# nrf54lm20a_enga_application register map
Vendor: Nordic Semiconductor; Series: nrf54l; File version: 1
CPU: CM33 r0p4, little endian, MPU, FPU, 3 interrupt priority bits, 270 interrupts, 4 SAU regions
Registers are 32-bit, read-write, reset 0x0 unless marked. A register's access mark holds for its fields unless they carry their own. Offsets are from the block's base; [hi:lo] are bit positions; lines under a group give offsets from that group; {n}, {i} and the like mark numbered series; 'fields as' and 'values as' point back to an identical list.

## GLOBAL_RADIO_NS (part 3 of 4) — 2.4 GHz radio 0
Base 0x4008A000
Same registers: GLOBAL_RADIO_S 0x5008A000
0x7D0 RXAGC group — Unspecified
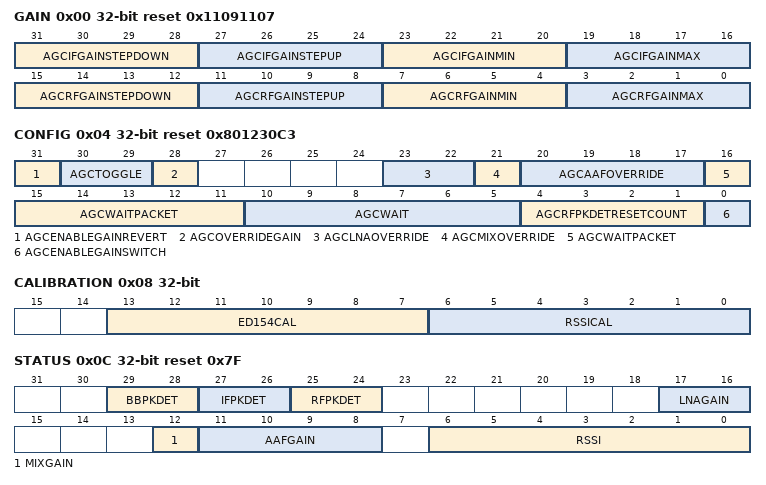
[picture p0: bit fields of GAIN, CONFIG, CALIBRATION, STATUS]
  0x00 GAIN reset 0x11091107 — Gain boundary settings and gain steps
    [31:28] AGCIFGAINSTEPDOWN — gain step for decreasing IF gain
    [27:24] AGCIFGAINSTEPUP — gain step for increasing IF gain
    [23:20] AGCIFGAINMIN — Minimum gain of IF gain
    [19:16] AGCIFGAINMAX — Maximum gain of IF gain
    [15:12] AGCRFGAINSTEPDOWN — gain step for decreasing RF gain
    [11:8] AGCRFGAINSTEPUP — gain step for increasing RF gain
    [7:4] AGCRFGAINMIN — Minimum gain of RF gain
    [3:0] AGCRFGAINMAX — Maximum gain of RF gain
  0x04 CONFIG reset 0x801230C3 — Configuration to adjust gain control loop
    [31] AGCENABLEGAINREVERT — Gain reversion. 0: reduce IF gain before RF gain, 1: reduce RF gain before IF gain.
    [30:29] AGCTOGGLE — Enable(1) or disable(0) functional testmode for AGC
    [28] AGCOVERRIDEGAIN — 0: AGC takes control of all gains, 1: Control all gains (aafGain, mixGain, lnaGain) from registers
    [23:22] AGCLNAOVERRIDE — Override value for lnaGain
    [21] AGCMIXOVERRIDE — Override value for mixGain
    [20:17] AGCAAFOVERRIDE — Override value for aafGain
    [16:11] AGCWAITPACKET — The number of clock cycles between each adjustment of the gain while addressMatch is high
    [10:5] AGCWAIT — The number of clock cycles between each adjustment of the gain while addressMatch is low
    [4:1] AGCRFPKDETRESETCOUNT — The number of clock cycles after the adjustment of gain that the reset signal to the RF peak detector is set high
    [0] AGCENABLEGAINSWITCH — Causes the RF gain to be decreased and the IF gain to be increased if the overall gain can be maintained
  0x08 CALIBRATION — Calibrate RSSI and Energy Detect values
    [13:7] ED154CAL — 802154 Energy Detect calibration value
    [6:0] RSSICAL — RSSI calibration value (this field affects the value of both RSSISAMPLE and EDSAMPLE)
  0x0C STATUS ro reset 0x7F — Readout latest gain control status
    [29:28] BBPKDET — BB peak detector output. Represent state[1:0] in RxAgc.
    [27:26] IFPKDET — IF peak detector output. Represent state[3:2] in RxAgc.
    [25:24] RFPKDET — RF peak detector output after sync. Represent state[5:4] in RxAgc.
    [17:16] LNAGAIN — Raw LNA gain status
    [12] MIXGAIN — Raw mixer gain status
    [11:8] AAFGAIN — Raw AAF gain status
    [6:0] RSSI — Raw status of received signal strength indicator, directly from RxAgc without buffering
0x7E4 RXIF group — Unspecified
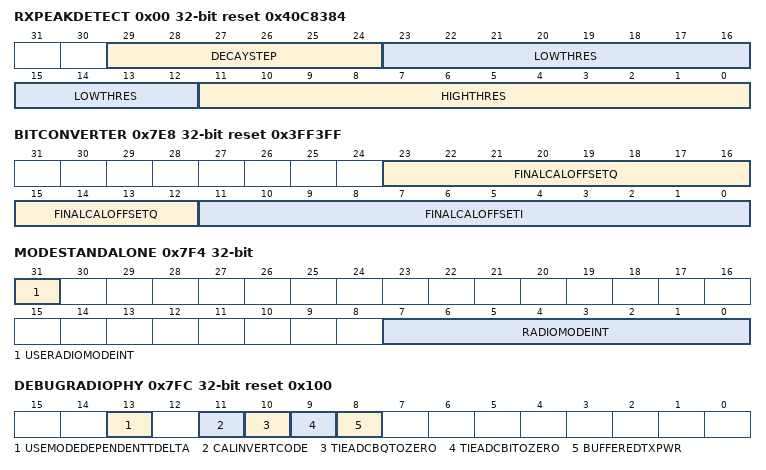
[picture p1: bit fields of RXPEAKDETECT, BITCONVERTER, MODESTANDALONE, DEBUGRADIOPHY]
  0x00 RXPEAKDETECT reset 0x40C8384 — Configuration of IF Rx peak detector
    [29:24] DECAYSTEP — Constant output reduction step
    [23:12] LOWTHRES — Low threshold of IF peak detector. This valued is based on the 11-bits ADC of SPHYNX_ANA.
    [11:0] HIGHTHRES — High threshold of IF peak detector. This valued is based on the 11-bits ADC of SPHYNX_ANA.
0x7E8 BITCONVERTER reset 0x3FF3FF — Configuration of ADC output to digital front-end
  [23:12] FINALCALOFFSETQ — ADC offset compensation of channel Q (unsigned)
  [11:0] FINALCALOFFSETI — ADC offset compensation of channel I (unsigned)
0x7F4 MODESTANDALONE — Data rate and modulation when SPHYNX in standalone mode
  [31] USERADIOMODEINT — 0: use radioMode/radioModeUpdate from port (controlled from top), 1: use radioMode/radioModeUpdate from registers in this IP
  [7:0] RADIOMODEINT — Internal radio mode consists of sSel, zeroIf, deModN and mode[3:0]
0x7FC DEBUGRADIOPHY reset 0x100 — Debug for radio PHY
  [13] USEMODEDEPENDENTTDELTA — 1: use TDELTAPIPE and TDELTAPWRDNPA from MODEDEPENDENT register instead of TIMINGTX2
  [11] CALINVERTCODE — 1: Invert all calibration codes
  [10] TIEADCBQTOZERO — 0: output normal adcBinaryBQ, 1: tie adcBinaryBQ to zero
  [9] TIEADCBITOZERO — 0: output normal adcBinaryBI, 1: tie adcBinaryBI to zero
  [8] BUFFEREDTXPWR — Set to high to buffer TXPOWER so that sub-modules in the MMI will only update next tx power config at TX_EN, RX_EN and LB_EN. Set to low if special test is needed for Tx test.
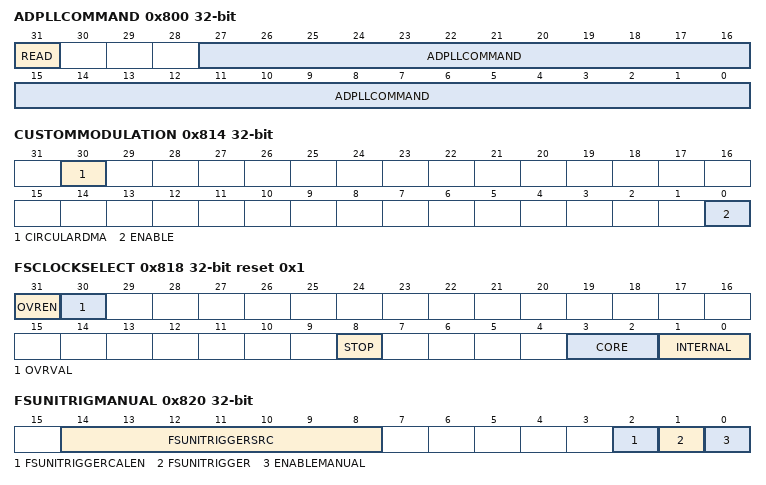
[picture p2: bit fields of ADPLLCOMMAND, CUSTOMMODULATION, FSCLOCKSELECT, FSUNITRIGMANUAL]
0x800 ADPLLCOMMAND — Send or receive command directly to the AdPll digital island. Only write to this register when FSASYNCBUSBUSY returns 0
  [31] READ — When 1, a read transaction is initiated. When the event COMPLETETRANS is set, read back this register
  [27:0] ADPLLCOMMAND — Controls the asynch interface, bits[27:16] are address, bits [15:0] are command/data field
0x804 FSFREQFINETUNE — Allows fine-tuning the RF frequency with a very fine resolution
  [12:0] FSFREQFINETUNE — 2-complement number for fine-tuning the frequency in steps of 488.28 Hz
0x808 DEVIATION reset 0x55 — Frequency deviation for modulation
  [9:0] DEVIATION
0x80C MODRATE reset 0x2 — Select modulation rate
  [2:0] MODRATE
    0=250Kbit (250 kbps); 1=500Kbit (500 kbps); 2=1Mbit (1 Mbps); 3=2Mbit (2 Mbps); 4=4Mbit (4 Mbps)
0x810 MODFILTERING reset 0x2 — Select gaussian filtering mode
  [2:0] MODFILTERING
    0=None (No filtering); 1=1bt00 (Gfsk Bt=1.00); 2=0bt60 (Gfsk Bt=0.60); 3=2bt00 (Gfsk Bt=2.00); 4=0bt40 (Gfsk Bt=0.40); 5=0bt45 (Gfsk Bt=0.45); 6=0bt50 (Gfsk Bt=0.50); 7=0bt55 (Gfsk Bt=0.55)
0x814 CUSTOMMODULATION — Enable reading from memory and passing data over to AdPll
  [30] CIRCULARDMA — If set to 1, the END event of the DMA will trigger the START task in order to transmit the same data over and over again (only works if DmaChannelPeripheral is inside AdPllCompanion)
  [0] ENABLE — Enable reading from memory and passing data over to AdPll
    0=Disabled (Custom modulation disabled); 1=Enabled (Custom modulation enabled)
0x818 FSCLOCKSELECT reset 0x1 — Set the clock source for the AdPll digital island
  [31] OVREN — Override enable for setting the clock switch. If 0, fsStart decides which clock to use. If 1, FSCLOCKSELECT.OVRVAL selects which clock to use
  [30] OVRVAL — Used instead of 'fsStart' if FSCLOCKSELECT.OVREN is set
  [8] STOP — Force-stopping the clock internally in the AdPll island
  [3:2] CORE — Set the clock source for the AdPll digital island when fsStart is low
  [1:0] INTERNAL — Set the clock source for the AdPll digital island when fsStart is high
0x81C FSUNITRIGCALVAL ro — Read the calibrated value for the universal trigger
  [4:0] FSUNITRIGCALVAL
0x820 FSUNITRIGMANUAL — Manual control of the uni trigger signals. Note that fsUniTriggerCalWord is controlled by writing to the separate register FSUNITRIGCALVAL
  [14:8] FSUNITRIGGERSRC — The fsUniTriggerCalSrc signal when using manual control
  [2] FSUNITRIGGERCALEN — The fsUniTriggerCalEn signal when using manual control
  [1] FSUNITRIGGER — The fsUniTrigger signal when using manual control
  [0] ENABLEMANUAL — Enable manual control
0x824 FSUNITRIGCALOUT ro — Read the signal directly from fsUniTriggerCalOut
  [1:0] FSUNITRIGCALOUT — Read the raw fsUniTriggerCalOut value
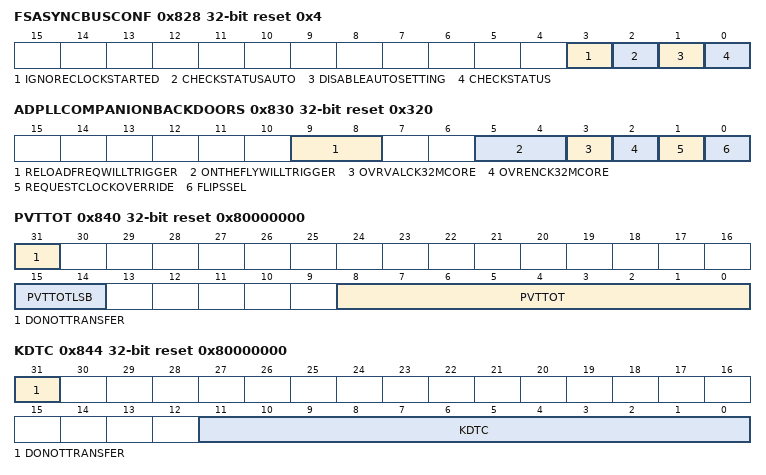
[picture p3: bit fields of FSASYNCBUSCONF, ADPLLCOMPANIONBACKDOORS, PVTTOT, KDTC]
0x828 FSASYNCBUSCONF reset 0x4 — Some special settings for the asynchronous bus configuration
  [3] IGNORECLOCKSTARTED — The bus scheduler will not wait for AdPll to say clockStarted
  [2] CHECKSTATUSAUTO — When 1, check the first transaction during sending auto. If errorenous stop the state machine
  [1] DISABLEAUTOSETTING — Do not send settings at the beginning to AdPll
  [0] CHECKSTATUS — When 1, every write transaction uses 8 x 32 MHz clock cycles instead of 4 x 32 MHz clock cycles. Confirmation is received whether the transaction was actually received by AdPll.
0x82C FSASYNCBUSBUSY ro reset 0x1 — Status bit indicating whether the bus is currently busy or not
  [0] FSASYNCBUSBUSY — Whether the bus is currently busy or not
0x830 ADPLLCOMPANIONBACKDOORS reset 0x320 — This value is written to the AdPll when powering up the digital island
  [9:8] RELOADFREQWILLTRIGGER — 0: no relock, 1: first gear of TRK, 2: back to ACQ, 3: back to full lock
  [5:4] ONTHEFLYWILLTRIGGER — 0: no relock, 1: first gear of TRK, 2: back to ACQ, 3: back to full lock
  [3] OVRVALCK32MCORE — Whether ck32MCore is active or not when OVRENCK32MCORE is set. See also description of OVRENCK32MCORE
  [2] OVRENCK32MCORE — Make it possible to manually control whether ck32MCore is sent to the AdPll digital island. Needed to test complete clock silence in the AdPll island. It can also be used to enable the clock activity on the clock net even when the clock is not selected.
  [1] REQUESTCLOCKOVERRIDE — In normal operation we request clock when pwrupFsLdoDig0 is set. By setting this to 1, we will request clock even when pwrupFsLdoDig0. This may be useful for current measurements of FS_DIG
  [0] FLIPSSEL — If 0, we flip the interpretation of the sSel signal (to work around a bug if we have managed to flip it somewhere in the design process)
0x840 PVTTOT reset 0x80000000 — This value is written to the AdPll when powering up the digital island
  [31] DONOTTRANSFER — When 1, we do not transfer this word to AdPll at power up
  [15:14] PVTTOTLSB — Optional LSBs for PVTTOT for increased resolution. Added at 15:14 in order TO NOT BREAK BACKWARDS COMPATIBILITY causing existing production trim tests to break
  [8:0] PVTTOT — The ratio between PVT and the total cap ratio. Used for Estkmod, Estkdtc and TdcReadout
0x844 KDTC reset 0x80000000 — This value is written to the AdPll when powering up the digital island
  [31] DONOTTRANSFER — When 1, we do not transfer this word to AdPll at power up
  [11:0] KDTC — The estimated kDTV value in typical
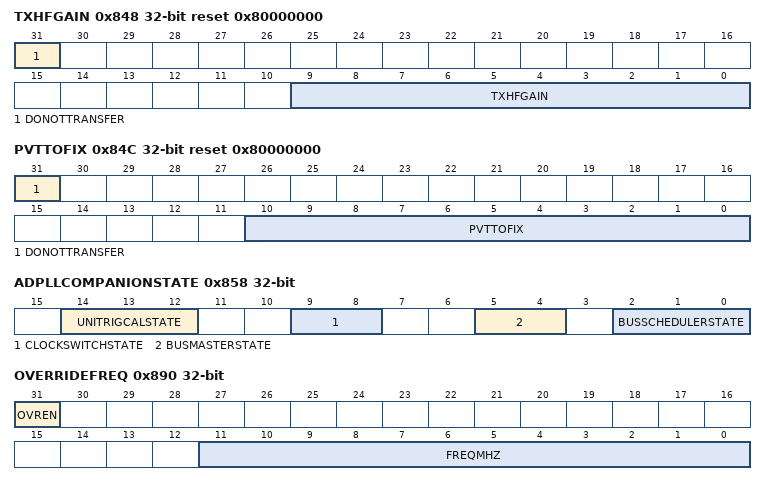
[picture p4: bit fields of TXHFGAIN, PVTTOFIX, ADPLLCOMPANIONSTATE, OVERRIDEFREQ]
0x848 TXHFGAIN reset 0x80000000 — This value is written to the AdPll when powering up the digital island
  [31] DONOTTRANSFER — When 1, we do not transfer this word to AdPll at power up
  [9:0] TXHFGAIN — The gain for the HF path
0x84C PVTTOFIX reset 0x80000000 — This value is written to the AdPll when powering up the digital island
  [31] DONOTTRANSFER — When 1, we do not transfer this word to AdPll at power up
  [10:0] PVTTOFIX — Calibration value for the PLL
0x850 TRACING — Enable tracing from AdPll
  [0] ENABLE
0x854 IFFREQ — Select between two different IF frequencies
  [1:0] IFFREQ — Select which IF frequency to use
    0=1 MHz IF; 1=2 MHz IF; 3=4 MHz IF
0x858 ADPLLCOMPANIONSTATE ro — State in the AdPllCompanion state machines
  [14:12] UNITRIGCALSTATE — The state of the universal trigger calibration routine
  [9:8] CLOCKSWITCHSTATE — The state of the clock switching state machine
  [5:4] BUSMASTERSTATE — The state of the async bus master
  [2:0] BUSSCHEDULERSTATE — The state of the state machine which sends commands automatically at startup
0x870 RELOADFREQINTERNAL — Non-official task: AdPll will reread the frequency input signal
  [0] TRIGGER
0x874 UNITRIGCALSTART — Non-official task: Start automatic universal trigger calibration
  [0] TRIGGER
0x878 FSSENDSETTINGS — Non-official task: Send the auto-settings to AdPll again. This also happens at every startup
  [0] TRIGGER
0x87C CHANGEPHASEINTERNAL — Non-official task: AdPll will change the phase as given by the internal AdPll register PHASE_CHANGE
  [0] TRIGGER
0x880 UNITRIGCALDONE — Non-official event: Start automatic universal trigger calibration
  [0] VAL
0x884 REJECTEDTRANS — Non-official event: The command written to AdPll was rejected because of an ongoing transaction
  [0] VAL
0x888 COMPLETETRANS — Non-official event: Completed a transaction to AdPll successfully (only when CHECKSTATUS is set)
  [0] VAL
0x88C FAILEDTRANS — Non-official event: Did not successfully complete a transaction to AdPll. (only when CHECKSTATUS is set)
  [0] VAL
0x890 OVERRIDEFREQ — Raw frequency configuration which also allows selecting frequency outside the 2.4 GHz band
  [31] OVREN — When 1, the fequency specified by OVERRIDEFREQ.FREQMHZ and FSFREQFINETUNE is used
  [11:0] FREQMHZ — Select frequency in MHz. This is a debug feature and only certain band regions will be available on different devices. The users is expected to know what is possible if using this register.
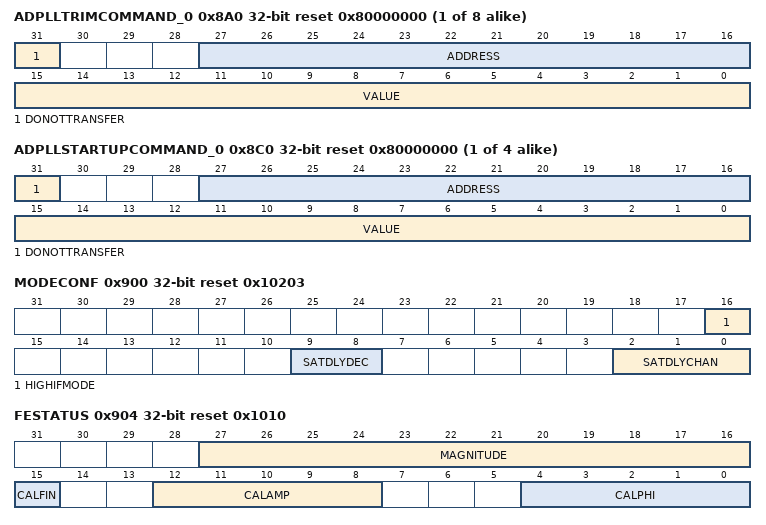
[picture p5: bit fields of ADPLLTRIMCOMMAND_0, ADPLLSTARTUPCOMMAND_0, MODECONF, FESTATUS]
{0x8A0+4i} ADPLLTRIMCOMMAND_{i} reset 0x80000000 (i=0..7) — This value is written to the AdPll when powering up the digital island. Never reset with SOFTRESET.
  [31] DONOTTRANSFER — When 1, we do not transfer this word to AdPll at power up
  [27:16] ADDRESS — The address of the digital island to write to
  [15:0] VALUE — The value to be written the register in the digital island
{0x8C0+4i} ADPLLSTARTUPCOMMAND_{i} reset 0x80000000 (i=0..3) — This value is written to the AdPll when powering up the digital island
  fields as ADPLLTRIMCOMMAND_0
0x8DC ADPLLCOMPANIONINTEN — Unspecified
  [3:0] EVENTS — Interrupt enable register for events (unused since IRQ not connected)
0x8E0 ADPLLCOMPANIONINTENSET write-1-sets — Unspecified
  [3:0] EVENTS — Interrupt set register for events (unused since IRQ not connected)
0x8E4 ADPLLCOMPANIONINTENCLR write-1-clears — Unspecified
  [3:0] EVENTS — Interrupt clear register for events (unused since IRQ not connected)
0x8E8 ADPLLCOMPANIONINTPEND ro — Unspecified
  [3:0] EVENTS
0x900 MODECONF reset 0x10203 — Mode specific configuration regiser
  [16] HIGHIFMODE — Selects mixing frequency. Setting this register to 0 halves the mixing frequency.
  [9:8] SATDLYDEC — Mode dependent saturation delay in decimation filters for different modes
  [2:0] SATDLYCHAN — Mode dependent saturation delay for different modes
0x904 FESTATUS ro reset 0x1010 — Frontend readout register
  [27:16] MAGNITUDE — Magnitude output from BB peak detector
  [15] CALFIN — High when IQCal search finished
  [12:8] CALAMP — calAmp from IQCal
  [4:0] CALPHI — calPhi from IQCal
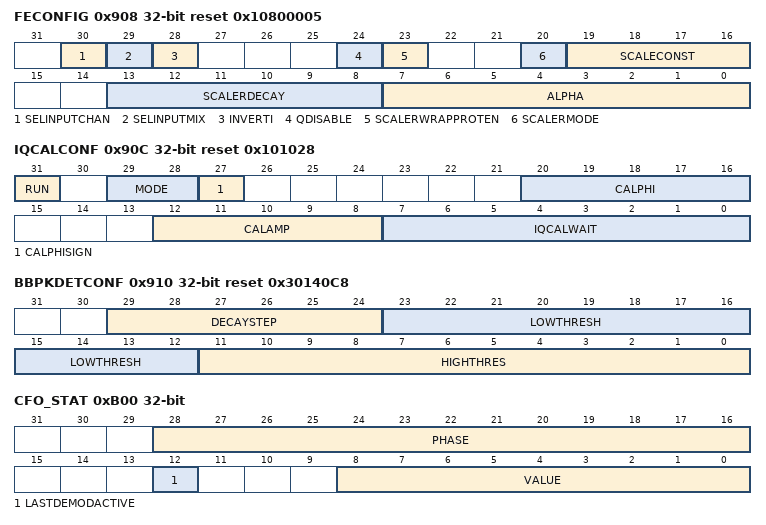
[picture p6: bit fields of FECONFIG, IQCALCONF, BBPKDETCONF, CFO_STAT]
0x908 FECONFIG reset 0x10800005 — Config register
  [30] SELINPUTCHAN — Channel Filters Input Select between Mixer and Injection DMA, i.e., SELINPUTCHAN = 0 for Mixer; SELINPUTCHAN = 1 for Injection DMA
  [29] SELINPUTMIX — Mixer Input Select between Decimator's Output and Injection DMA, i.e., SELINPUTMIX = 0 for Decimator; SELINPUTMIX = 1 for Injection DMA
  [28] INVERTI — Invert I channel in case Q channel leads I
  [24] QDISABLE — Disable Q samples to save power
  [23] SCALERWRAPPROTEN — Wraparound protection in IQ Scaler.
    0=Disabled (Disable wraparound protection. Not recommended to disable with constant scaling.); 1=Enabled (Disable wraparound protection. Scaled input is set to max or min instead of wrapping around.)
  [20] SCALERMODE — Mode for narrow scaling output.
    0=Disabled (Classic log based scaling mode.); 1=Enabled (LUT based scaling mode.)
  [19:16] SCALECONST — A constant scaling that overrides dynamic scaling behaviour in the IQ Scaler. Value != 0 enables constant scaling.
  [13:8] SCALERDECAY — The number of clock cycles to wait before stepping down the internal memory for the scaling. The value 0 means that the decay feature is off.
  [7:0] ALPHA — Alpha for IIR filter used in logMag calculation
0x90C IQCALCONF reset 0x101028 — Gain and phase mismatch calibration control for I and Q
  [31] RUN — Run I and Q calibration procedure
    0=Stored (Using stored values for calPhi and calAmp); 1=Calib (Running calibration)
  [29:28] MODE — IQCal search mode
    0=Optimized search algorithm; 1=Exhaustive search; 2=Cancellation (Optimized search with cancellation.)
  [27] CALPHISIGN — Sign of calPhi value
  [20:16] CALPHI — Stored calPhi value
  [12:8] CALAMP — Stored calAmp value
  [7:0] IQCALWAIT — Settling time (in number of 16 MHz clock periods) for rssi input to stabilize
0x910 BBPKDETCONF reset 0x30140C8 — Configuration for baseband peak detector
  [29:24] DECAYSTEP — Constant output reduction step
  [23:12] LOWTHRESH — Low threshold for peak detector
  [11:0] HIGHTHRES — High threshold for peak detector
0x914 FILTERS group — Unspecified
  0x00 OUTTOMIX group — Unspecified
    0x00 CKSEL reset 0x2 — Clock select register for the output outToMix
      [2:0] CKSEL — Number of times to divide the base clock rate by 2. Exception: highest value gives BYPASS, ie. clock is disabled and data out is assigned directly from data in.
        0=ClkSel32M (CKSEL_32M); 1=ClkSel16M (CKSEL_16M); 2=ClkSel8M (CKSEL_8M); 3=ClkSel4M (CKSEL_4M); 4=ClkSel2M (CKSEL_2M); 5=ClkSel1M (CKSEL_1M); 6=ClkSel500K (CKSEL_500K); 7=ClkSelBypass (CKSEL_BYPASS)
  0x04 OUTTOBB group — Unspecified
    0x00 CKSEL reset 0x2 — Clock select register for the output outToBB
      fields as FILTERS.OUTTOMIX.CKSEL
    0x04 SOURCE reset 0x6 — Source select register for the output outToBB
      [4:0] SOURCE — Data source select
        30=SRC_INFROMMIX (NOT LEGAL); 31=SRC_INFROMADC (NOT LEGAL); 0=SRC_DECFIR0 (NOT LEGAL); 1=SRC_DECFIR1 (NOT LEGAL); 2=SRC_DECFIR2 (NOT LEGAL); 3=SRC_IIR0 (NOT LEGAL); 4=SRC_IIR1 (NOT LEGAL); 5=SrcNotchIIR0; 6=SrcDecFIR
  0x0C OUTPEAKDET group — Unspecified
    0x00 CKSEL reset 0x2 — Clock select register for the output outPeakDet
      fields as FILTERS.OUTTOMIX.CKSEL
    0x04 SOURCE reset 0x5 — Source select register for the output outPeakDet
      fields as FILTERS.OUTTOBB.SOURCE
  0x14 DECFIR0 group — Unspecified
    0x00 CKSEL reset 0x7 — Clock select register for the PUnit decFIR0 of type IP_FIR
      fields as FILTERS.OUTTOMIX.CKSEL
    0x04 CONTROL reset 0x2 — Control register for the PUnit decFIR0 of type IP_FIR
      [1:0] TAPSEL — Tap-select: number of active taps minus 2
  0x30 DECFIR1 group — Unspecified
    0x00 CKSEL — Clock select register for the PUnit decFIR1 of type IP_FIR
      fields as FILTERS.OUTTOMIX.CKSEL
    0x04 CONTROL reset 0x4 — Control register for the PUnit decFIR1 of type IP_FIR
      [2:0] TAPSEL — Tap-select: number of active taps minus 2
  0x4C DECFIR2 group — Unspecified
    0x00 CKSEL reset 0x1 — Clock select register for the PUnit decFIR2 of type IP_FIR
      fields as FILTERS.OUTTOMIX.CKSEL
    0x04 CONTROL reset 0x4 — Control register for the PUnit decFIR2 of type IP_FIR
      [2:0] TAPSEL — Tap-select: number of active taps minus 2
  0x68 IIR0 group — Unspecified
    0x00 CKSEL reset 0x2 — Clock select register for the PUnit IIR0 of type IP_IIR2
      fields as FILTERS.OUTTOMIX.CKSEL
    0x04 STATUS write-1-clears — Status register for the PUnit IIR0 of type IP_IIR2
      [1:0] IQSATURATION — Saturation status for I/Q (bit 0/1) component (bitwise write 1 to clear)
    0x08 COEFFSB0 reset 0x80 — Coefficient register B0 for the PUnit IIR0 of type IP_IIR2
      [11:0] COEFFB0 — Signed filter coefficient B0
    0x0C COEFFSB1 reset 0x80 — Coefficient register B1 for the PUnit IIR0 of type IP_IIR2
      [11:0] COEFFB1 — Signed filter coefficient B1
    0x10 COEFFSB2 — Coefficient register B2 for the PUnit IIR0 of type IP_IIR2
      [11:0] COEFFB2 — Signed filter coefficient B2
    0x14 COEFFSA1 reset 0xD00 — Coefficient register A1 for the PUnit IIR0 of type IP_IIR2
      [11:0] COEFFA1 — Signed filter coefficient A1
    0x18 COEFFSA2 — Coefficient register A2 for the PUnit IIR0 of type IP_IIR2
      [11:0] COEFFA2 — Signed filter coefficient A2
  0x84 IIR1 group — Unspecified
    0x00 CKSEL reset 0x2 — Clock select register for the PUnit IIR1 of type IP_IIR2
      fields as FILTERS.OUTTOMIX.CKSEL
    0x04 STATUS write-1-clears — Status register for the PUnit IIR1 of type IP_IIR2
      fields as FILTERS.IIR0.STATUS
    {0x8+4k} COEFFSB{k} reset 0x60 (k=0..2) — Coefficient register B{k} for the PUnit IIR1 of type IP_IIR2
      [11:0] COEFFB{k} — Signed filter coefficient B{k}
    0x14 COEFFSA1 reset 0xA00 — Coefficient register A1 for the PUnit IIR1 of type IP_IIR2
      [11:0] COEFFA1 — Signed filter coefficient A1
    0x18 COEFFSA2 reset 0x300 — Coefficient register A2 for the PUnit IIR1 of type IP_IIR2
      [11:0] COEFFA2 — Signed filter coefficient A2
  0xA0 NOTCHIIR0 group — Unspecified
    0x00 CKSEL reset 0x2 — Clock select register for the PUnit notchIIR0 of type IP_IIR2
      fields as FILTERS.OUTTOMIX.CKSEL
    0x04 SOURCE reset 0x4 — Source select register for the PUnit notchIIR0 of type IP_IIR2
      [4:0] SOURCE — Data source select
        30=SRC_INFROMMIX (NOT LEGAL); 31=SRC_INFROMADC (NOT LEGAL); 0=SRC_DECFIR0 (NOT LEGAL); 1=SRC_DECFIR1 (NOT LEGAL); 2=SRC_DECFIR2 (NOT LEGAL); 3=SRC_IIR0 (NOT LEGAL); 4=SrcIIR1; 5=SRC_NOTCHIIR0 (NOT LEGAL); 6=SrcDecFIR
    0x08 STATUS write-1-clears — Status register for the PUnit notchIIR0 of type IP_IIR2
      fields as FILTERS.IIR0.STATUS
    0x0C COEFFSB0 reset 0x3C0 — Coefficient register B0 for the PUnit notchIIR0 of type IP_IIR2
      [11:0] COEFFB0 — Signed filter coefficient B0
    0x10 COEFFSB1 reset 0xAB0 — Coefficient register B1 for the PUnit notchIIR0 of type IP_IIR2
      [11:0] COEFFB1 — Signed filter coefficient B1
    0x14 COEFFSB2 reset 0x3C0 — Coefficient register B2 for the PUnit notchIIR0 of type IP_IIR2
      [11:0] COEFFB2 — Signed filter coefficient B2
    0x18 COEFFSA1 reset 0xAB0 — Coefficient register A1 for the PUnit notchIIR0 of type IP_IIR2
      [11:0] COEFFA1 — Signed filter coefficient A1
    0x1C COEFFSA2 reset 0x380 — Coefficient register A2 for the PUnit notchIIR0 of type IP_IIR2
      [11:0] COEFFA2 — Signed filter coefficient A2
  0xC0 DECFIR group — Unspecified
    0x00 CKSEL reset 0x7 — Clock select register for the PUnit decFIR of type IP_FIR
      fields as FILTERS.OUTTOMIX.CKSEL
    0x04 SOURCE reset 0x5 — Source select register for the PUnit decFIR of type IP_FIR
      [4:0] SOURCE — Data source select
        30=SRC_INFROMMIX (NOT LEGAL); 31=SRC_INFROMADC (NOT LEGAL); 0=SRC_DECFIR0 (NOT LEGAL); 1=SRC_DECFIR1 (NOT LEGAL); 2=SRC_DECFIR2 (NOT LEGAL); 3=SRC_IIR0 (NOT LEGAL); 4=SrcIIR1; 5=SrcNotchIIR0; 6=SRC_DECFIR (NOT LEGAL)
    0x08 CONTROL reset 0x4 — Control register for the PUnit decFIR of type IP_FIR
      [2:0] TAPSEL — Tap-select: number of active taps minus 2
    0x0C COEFFS0 reset 0x4 — Coefficient register 0 for the PUnit decFIR of type IP_FIR
      [5:0] COEFF0 — Signed filter coefficient 0
    0x10 COEFFS1 reset 0x10 — Coefficient register 1 for the PUnit decFIR of type IP_FIR
      [5:0] COEFF1 — Signed filter coefficient 1
    0x14 COEFFS2 reset 0x18 — Coefficient register 2 for the PUnit decFIR of type IP_FIR
      [5:0] COEFF2 — Signed filter coefficient 2
0xB00 CFO_STAT ro — Carrier freq. offset estimate
  [28:16] PHASE — Readout of last valid phase set in correlator (hypermode only) (signed)
  [12] LASTDEMODACTIVE — 0: Standard mode was used last 1: Hypermode was last used
  [8:0] VALUE — Readout of last valid decision level set in BitSlicer (signed)
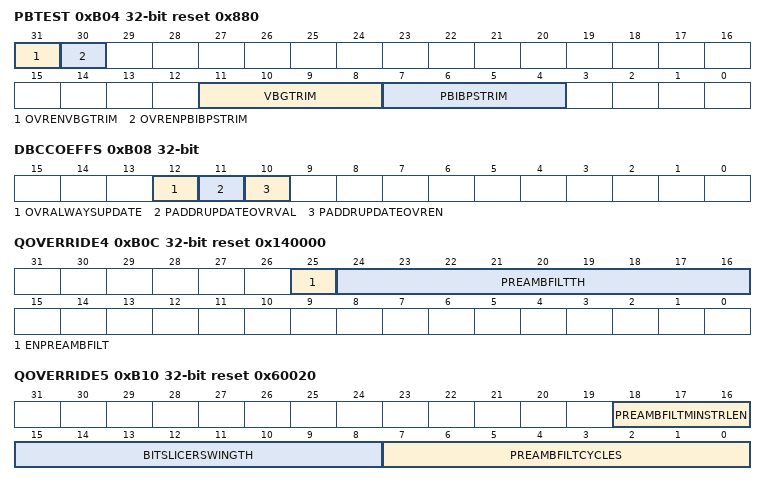
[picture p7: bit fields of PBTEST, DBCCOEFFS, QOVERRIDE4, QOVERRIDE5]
0xB04 PBTEST reset 0x880 — Test: PB calibration
  [31] OVRENVBGTRIM — if '1' enable override for VBGTRIM
  [30] OVRENPBIBPSTRIM — if '1' enable override for PBIBPSTRIM
  [11:8] VBGTRIM — Trim code for VBG to FS_VCOREG
  [7:4] PBIBPSTRIM — Trim code for IBPS currents
0xB08 DBCCOEFFS — Test and Debug: DBC coefficients override
  [12] OVRALWAYSUPDATE — Zero means coefficients only updated when needed (default), set to 1 coefficients are always updated when the radio is enabled.
  [11] PADDRUPDATEOVRVAL
  [10] PADDRUPDATEOVREN
0xB0C QOVERRIDE4 reset 0x140000 — Trim value override register 4 for nRF52
  [25] ENPREAMBFILT — Enable preamble filter
  [24:16] PREAMBFILTTH — Threshold for the preamble filter
0xB10 QOVERRIDE5 reset 0x60020 — Trim value override register 5 for nRF52
  [18:16] PREAMBFILTMINSTRLEN — Override value for preambFiltMinStrLen
  [15:8] BITSLICERSWINGTH — Override value for bitSlicerSwingTh
  [7:0] PREAMBFILTCYCLES — Override value for preambFiltCycles
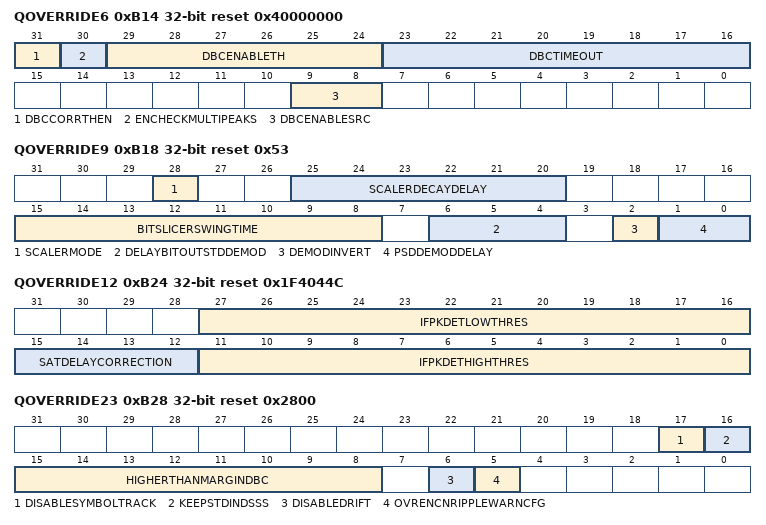
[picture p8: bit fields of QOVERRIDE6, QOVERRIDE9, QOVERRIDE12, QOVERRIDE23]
0xB14 QOVERRIDE6 reset 0x40000000 — Trim value override register 6 for nRF52
  [31] DBCCORRTHEN — Override value enable for DBCCORRTH and MFBSTRBOFFSET
  [30] ENCHECKMULTIPEAKS — Enable checking of several correlator peaks in hypermode
  [29:24] DBCENABLETH — Override value for correlator enable threshold
  [23:16] DBCTIMEOUT — Override value for correlator timeout,in bit periods (hypermode)
  [9:8] DBCENABLESRC — Override value for dbcEnableSrc
    0=Always on when not address match; 1=BBLogMag (When bbLogMag is above a threshold); 2=BitSlicerSwing (When a certain time has gone since the input to the bitslicer was above BITSLICERSWINGTH); 3=Both BBLogMag and BitSlicerSwing
0xB18 QOVERRIDE9 reset 0x53 — Trim value override register 9 for nRF52
  [28] SCALERMODE — Scaler mode. Set to 1 for LUT based scaling
  [25:20] SCALERDECAYDELAY — Decay delay for the IQ scaler
  [15:8] BITSLICERSWINGTIME
  [6:4] DELAYBITOUTSTDDEMOD — Override value for delayBitOutStdDemod (standard mode)
  [2] DEMODINVERT — Override value for demodInvert (standard and hyper)
  [1:0] PSDDEMODDELAY — Override value for psdDemodDelay (standard mode)
0xB24 QOVERRIDE12 reset 0x1F4044C — Trim value override register 12 for nRF52
  [27:16] IFPKDETLOWTHRES — Override value for IfpkDetLowThres
  [15:12] SATDELAYCORRECTION — Signed correction value for how much the saturation information is delayed from the input ADC samples to the samples being stored to RAM in direction finding operation
  [11:0] IFPKDETHIGHTHRES — Override value for IfpkDetHighThres
0xB28 QOVERRIDE23 reset 0x2800 — Trim value override register 23 for nRF52
  [17] DISABLESYMBOLTRACK — Disable symbol tracking for IEEE 802.15.4 and BLE LR 125K modes
  [16] KEEPSTDINDSSS — Keep standard demod in DSSS mode
  [15:8] HIGHERTHANMARGINDBC — Required peak height required for a double correlator peak to be considered higher than previous ones. The register value will be multiplied by 25 to obtain the actual margin. The bitfield is NOT subject to the enable override at bit position 31, and will always be enabled for hypermode.
  [6] DISABLEDRIFT — Disable option for RxDrift.
  [5] OVRENCNRIPPLEWARNCFG — Override enable for CNPEAKMINTHR and CNABSMAXTHR in the CNRIPPLEWARNCFG register
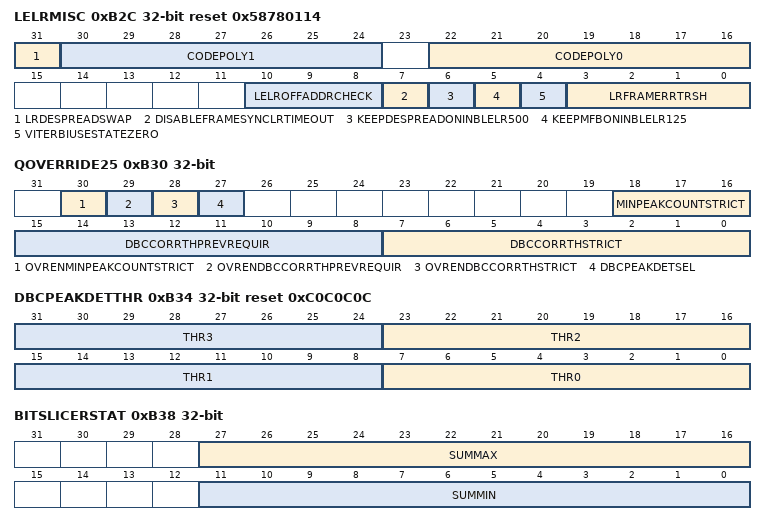
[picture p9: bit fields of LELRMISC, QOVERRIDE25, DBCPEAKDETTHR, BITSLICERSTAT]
0xB2C LELRMISC reset 0x58780114 — Miscellaneous Controls for Long Range
  [31] LRDESPREADSWAP — Swap de-spreader
  [30:24] CODEPOLY1 — Code Polynom 1
  [22:16] CODEPOLY0 — Code Polynom 0
  [10:8] LELROFFADDRCHECK — The number of chip periods earlier which it is allowed to declare frameSync in DecodeLELong
  [7] DISABLEFRAMESYNCLRTIMEOUT — Disable framesync timeout (early address match timeout) for BLE LR mode (hypermode).
  [6] KEEPDESPREADONINBLELR500 — Do not stop the clock to the Despreader in BLE LR 500 mode
  [5] KEEPMFBONINBLELR125 — Do not stop the clock to RxMFB in BLE LR 125 mode
  [4] VITERBIUSESTATEZERO — Use Viterbi state zero when flushing out bits for BLE LR
  [3:0] LRFRAMERRTRSH — Framer Receive Threshold
0xB30 QOVERRIDE25 — TODO
  [30] OVRENMINPEAKCOUNTSTRICT — Override enable for MINPEAKCOUNTSTRICT
  [29] OVRENDBCCORRTHPREVREQUIR — Override enable for DBCCORRTHPREVREQUIR
  [28] OVRENDBCCORRTHSTRICT — Override enable for DBCCORRTHSTRICT
  [27] DBCPEAKDETSEL — DBC peak detector selection
    0=Classic (Use classic peak detector (backward compatible behavior)); 1=Differential (Use differential peak detector)
  [18:16] MINPEAKCOUNTSTRICT — Min number of peaks to detect before resyncing to another preamble while already working on a previous preamble in BleLrx.
  [15:8] DBCCORRTHPREVREQUIR — Correlation threshold for double correlator used in BleLr mode to reject a later resync using DBCCORRTHSTRICT.
  [7:0] DBCCORRTHSTRICT — Correlation threshold for double correlator used in BleLr mode to resync to another preamble while already working on a previous preamble.
0xB34 DBCPEAKDETTHR reset 0xC0C0C0C — Thresholds for each peak detector instance
  [8n+7:8n] THR{n} (n=0..3) — Diff threshold {n}
0xB38 BITSLICERSTAT ro — Payload status
  [27:16] SUMMAX — Number of received ones
  [11:0] SUMMIN — Number of received zeros
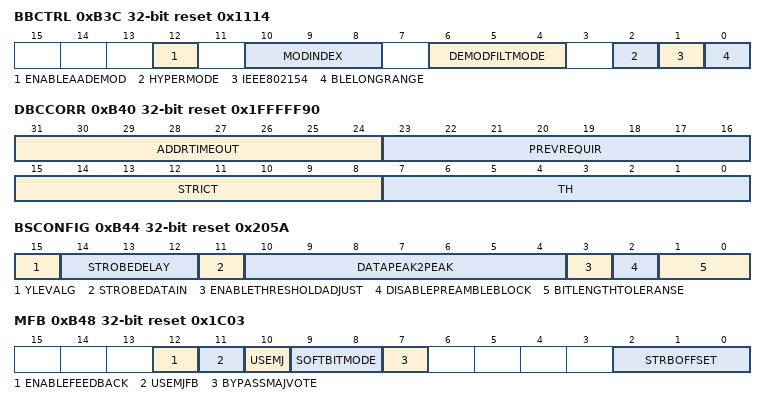
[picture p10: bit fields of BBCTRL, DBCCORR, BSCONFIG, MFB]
0xB3C BBCTRL reset 0x1114 — Miscellaneous mode bits
  [12] ENABLEAADEMOD — Enable buffering, decoding and address matching of first 16 bits of Access Address
    0=Disabled (First 16 bits of AA only qualified by DBC); 1=Enabled (First 16 bits of AA qualified by both DBC and MFB)
  [10:8] MODINDEX — Modulation index for RxDBCCoeffGen and RxMFB
    0=0h25 (Modulation index h=0.25); 1=0h32 (Modulation index h=0.32); 2=0h5 (Modulation index h=0.5); 3=1h0 (Modulation index h=1.0); 4=2h0 (Modulation index h=2.0)
  [6:4] DEMODFILTMODE — Decimation mode in PantherDemodFilt
    0=2M (Decimation mode 2M); 1=1M (Decimation mode 1M); 3=250K (Decimation mode 250K)
  [2] HYPERMODE — Enable Hyper demodulator
    0=Disabled (HYPERMODE_NO); 1=Enabled (HYPERMODE_YES)
  [1] IEEE802154 — Enable 15.4 mode (enabling both 15.4 and long range is not legal)
    0=Disabled (IEEE802154_NO); 1=Enabled (IEEE802154_YES)
  [0] BLELONGRANGE — Enable long range mode (enabling both 15.4 and long range is not legal)
    0=Disabled (BLELONGRANGE_NO); 1=Enabled (BLELONGRANGE_YES)
0xB40 DBCCORR reset 0x1FFFFF90 — Thresholds for the double correlator
  [31:24] ADDRTIMEOUT — Override value for address match timeout, [in bit periods] (hypermode). 0 means no timeout. If BALEN is 3, the actual value of DBCADDRTIMEOUT will be the value written to this register minus 8.
  [23:16] PREVREQUIR — Correlation threshold for double correlator used in BleLr mode to reject a later resync using DBCCORRTHSTRICT. Also applies for Ieee 802.15.4 mode
  [15:8] STRICT — Correlation threshold for double correlator used in BleLr mode to resync to another preamble while already working on a previous preamble. Also applies for Ieee 802.15.4 mode
  [7:0] TH — Correlation threshold for double correlator in normal operation
0xB44 BSCONFIG reset 0x205A — Bitslicer configuration
  [15] YLEVALG — Override for bsYlevAlg
  [14:12] STROBEDELAY — Override for bsStrobeDelay
  [11] STROBEDATAIN — Override for bsStrobeDataIn
  [10:4] DATAPEAK2PEAK — Override for bsDataPeak2Peak
  [3] ENABLETHRESHOLDADJUST — Override for bsEnableThresholdAdjust
  [2] DISABLEPREAMBLEBLOCK — Override for bsDisablePreambleBlock
  [1:0] BITLENGTHTOLERANSE — Override for bsBitLengthToleranse
0xB48 MFB reset 0x1C03 — Matched Filter Bank (MFB) configuration
  [12] ENABLEFEEDBACK — Enable decision feedback for matched filter bank
  [11] USEMJFB — Use hard bit from majority vote as the feedback inside the RxMFB. Use hard bit from soft bit generator otherwise.
  [10] USEMJ — Use hard bit from majority vote as the output of the RxMFB. Use hard bit from soft bit generator otherwise.
  [9:8] SOFTBITMODE — Method used for the softbit calulation
    0=Max (Softbit calculation in MFB uses the maximum); 1=Sum (Softbit calculation in MFB uses the sum); 2=WSum1 (Softbit calculation in MFB uses the weighted sum 1); 3=WSum2 (Softbit calculation in MFB uses the weighted sum 2)
  [7] BYPASSMAJVOTE — Bypass majority vote
    0=Pass (Majority vote); 1=Bypass through majority vote
  [2:0] STRBOFFSET — Override value for strobe offset
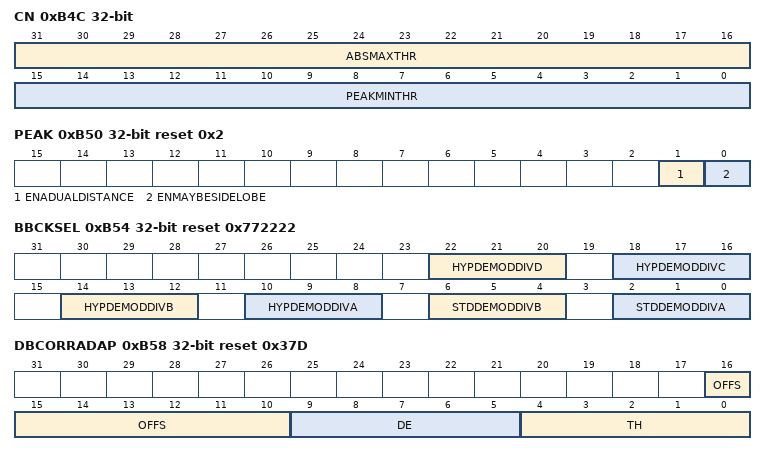
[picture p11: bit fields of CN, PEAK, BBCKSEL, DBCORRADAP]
0xB4C CN — Configuration for the CNRIPPLEWARN functionality used for BLE LR. Configuration is only enabled when OVRENCNRIPPLEWARNCFG in OVERRIDE23 is set
  [31:16] ABSMAXTHR — maximum baseline value before the peak at the double correlator output. if the baseline value is above the threshold, the following peak will be ignored. this value is ignored when CNABSMAXTHR is set to 0x0000.
  [15:0] PEAKMINTHR — Required peak height compared to baseline level measured just before the peak at the double correlator output. If the peak height is below the threshold, it will be ignored. This feature is disabled when CNPEAKMINTHR is set to 0x0000.
0xB50 PEAK reset 0x2 — Peak detector configuration
  [1] ENADUALDISTANCE — Allow dual distance between peaks
  [0] ENMAYBESIDELOBE — Ignore peaks from DBC which look like sidelobes
0xB54 BBCKSEL reset 0x772222 — Clock rates
  [22:20] HYPDEMODDIVD — Hyper demod clock divider D (max 4MHz)
    3=4M (Clock 4MHz); 4=2M (Clock 2MHz); 5=1M (Clock 1MHz); 6=500K (Clock 500kHz); 7=Disabled (Clock OFF)
  [18:16] HYPDEMODDIVC — Hyper demod clock divider C (max 8MHz)
    2=8M (Clock 8MHz); 3=4M (Clock 4MHz); 4=2M (Clock 2MHz); 5=1M (Clock 1MHz); 6=500K (Clock 500kHz); 7=Disabled (Clock OFF)
  [14:12] HYPDEMODDIVB — Hyper demod clock divider B
    0=32M (Clock 32MHz); 1=16M (Clock 16MHz); 2=8M (Clock 8MHz); 3=4M (Clock 4MHz); 4=2M (Clock 2MHz); 5=1M (Clock 1MHz); 6=500K (Clock 500kHz); 7=Disabled (Clock OFF)
  [10:8] HYPDEMODDIVA — Hyper demod clock divider A
    values as HYPDEMODDIVB
  [6:4] STDDEMODDIVB — Standard demod clock divider B
    values as HYPDEMODDIVB
  [2:0] STDDEMODDIVA — Standard demod clock divider A
    values as HYPDEMODDIVB
0xB58 DBCORRADAP reset 0x37D — Adaptive thresholds for double correlator.
  [16:10] OFFS — Offset for comparing between current and historical DBC magnitude
  [9:5] DE — A ratio to decay the DBC ration threshold when using adaptive threshold and a weak peak is found.
  [4:0] TH — A ratio to update the DBC ratio threshold when adaptive threshold is enabled and a strong peak is found. Fraction of highest correlator match historically seen. Setting of 0.90625 is default.
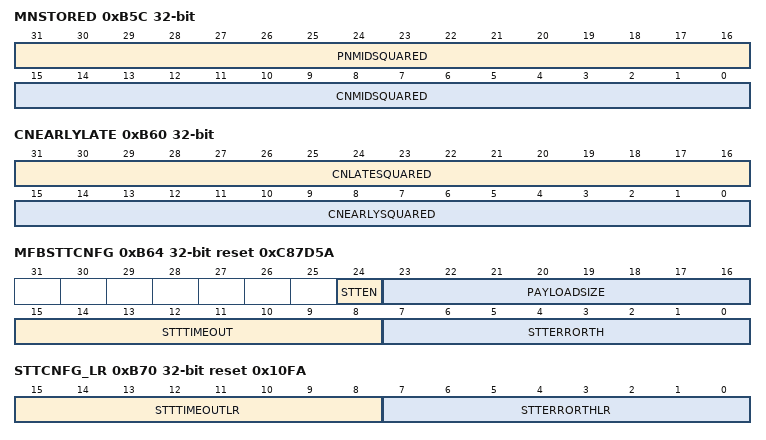
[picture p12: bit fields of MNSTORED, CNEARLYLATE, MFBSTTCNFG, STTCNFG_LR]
0xB5C MNSTORED ro — Stored value of Cn and Pn from the double correlator at the last detect
  [31:16] PNMIDSQUARED — Squared value of Pn which can be used to find Mn associated with the last double correlator detect
  [15:0] CNMIDSQUARED — Squared value of Cn which can be used to find Mn associated with the last double correlator detect
0xB60 CNEARLYLATE ro — The Cn value associated with the clock cycle before and after the actually double correlator peak was found (detect)
  [31:16] CNLATESQUARED — Squared value of Cn after the peak
  [15:0] CNEARLYSQUARED — Squared value of Cn before the peak
0xB64 MFBSTTCNFG reset 0xC87D5A — Matched Filter Bank (MFB) symbol time tracking configuration
  [24] STTEN — Enable for symbol time tracking logic in RxMFB.
  [23:16] PAYLOADSIZE — Minumum payload size for when STT is enabled
  [15:8] STTTIMEOUT — Period in bits where it is not allowed to set incStrb or decStrb
  [7:0] STTERRORTH — Strobe time tracking: strobe time error threshold
0xB68 RXAA write-0-clears — 32-bit Hyper Access Address as decoded; for 1M, 2M and 4M BLE and proprietary modes
  [31:0] VALUE
0xB70 STTCNFG_LR reset 0x10FA — Strobe time tracking configuration in long range mode
  [15:8] STTTIMEOUTLR — Strobe time tracking timeout in BLE LR mode
  [7:0] STTERRORTHLR — Strobe time tracking error threshold in BLE LR mode
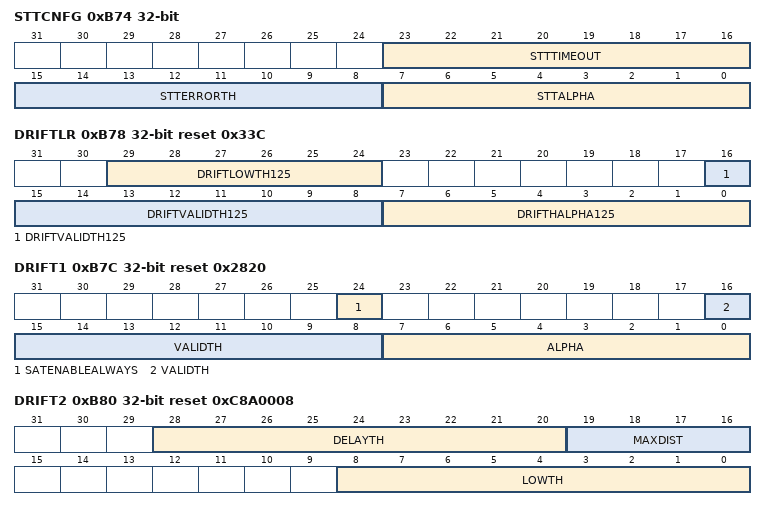
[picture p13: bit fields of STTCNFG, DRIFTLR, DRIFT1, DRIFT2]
0xB74 STTCNFG — Strobe time tracking Configuration (Symbol Timing)
  [23:16] STTTIMEOUT — Strobe time tracking: adjustment timeout (min distance in symbolperiods between strobe adjustments in same direction)
  [15:8] STTERRORTH — Strobe time tracking: strobe time error threshold
  [7:0] STTALPHA — Strobe time tracking: IIR filter alpha
0xB78 DRIFTLR reset 0x33C — Drift Controls in Long Range
  [29:24] DRIFTLOWTH125 — Value for driftLowTh, drift estimator (despreadLELLong)
  [16:8] DRIFTVALIDTH125 — Value for driftValidTh, drift estimator (despreadLELLong)
  [7:0] DRIFTHALPHA125 — Value for IIR feedback , drift estimator (despreadLELLong)
0xB7C DRIFT1 reset 0x2820 — Drift Estimator configuration
  [24] SATENABLEALWAYS — Enable saturation in drift calculator for all modes
  [16:8] VALIDTH — Value for driftValidTh, drift estimator (hypermode)
  [7:0] ALPHA — Value for IIR feedback , drift estimator (hypermode)
0xB80 DRIFT2 reset 0xC8A0008 — Drift Estimator configuration
  [28:20] DELAYTH — Value for driftDelayTh, drift estimator (hypermode)
  [19:16] MAXDIST — Value for driftMaxDist, drift estimator (hypermode)
  [8:0] LOWTH — Value for driftLowTh, drift estimator (hypermode)
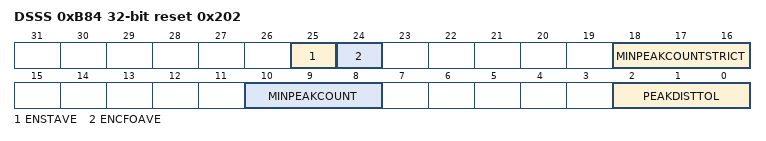
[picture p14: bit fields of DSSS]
0xB84 DSSS reset 0x202 — DSSS synchronizer trim values
  [25] ENSTAVE — Enable strobe time averaging
  [24] ENCFOAVE — Enable CFO averaging
  [18:16] MINPEAKCOUNTSTRICT — Min number of peaks to detect before resyncing to another preamble while already working on a previous preamble in BleLrx. Also applies for Ieee 802.15.4 mode
  [10:8] MINPEAKCOUNT — Minimum number of peaks
  [2:0] PEAKDISTTOL — Minimum tolerance of peak distance
